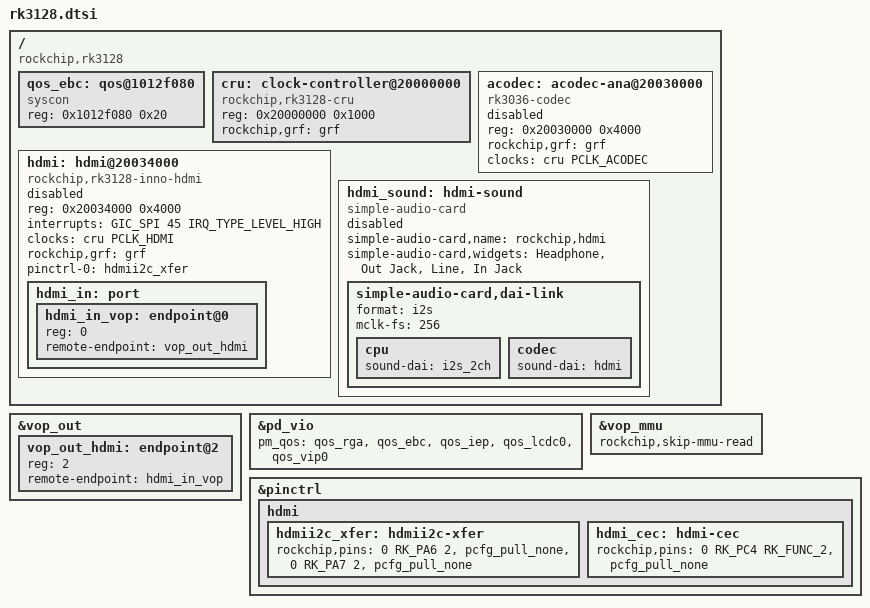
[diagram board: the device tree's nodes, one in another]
/*
 * This file is dual-licensed: you can use it either under the terms
 * of the GPL or the X11 license, at your option. Note that this dual
 * licensing only applies to this file, and not this project as a
 * whole.
 *
 *  a) This file is free software; you can redistribute it and/or
 *     modify it under the terms of the GNU General Public License as
 *     published by the Free Software Foundation; either version 2 of the
 *     License, or (at your option) any later version.
 *
 *     This file is distributed in the hope that it will be useful,
 *     but WITHOUT ANY WARRANTY; without even the implied warranty of
 *     MERCHANTABILITY or FITNESS FOR A PARTICULAR PURPOSE.  See the
 *     GNU General Public License for more details.
 *
 * Or, alternatively,
 *
 *  b) Permission is hereby granted, free of charge, to any person
 *     obtaining a copy of this software and associated documentation
 *     files (the "Software"), to deal in the Software without
 *     restriction, including without limitation the rights to use,
 *     copy, modify, merge, publish, distribute, sublicense, and/or
 *     sell copies of the Software, and to permit persons to whom the
 *     Software is furnished to do so, subject to the following
 *     conditions:
 *
 *     The above copyright notice and this permission notice shall be
 *     included in all copies or substantial portions of the Software.
 *
 *     THE SOFTWARE IS PROVIDED "AS IS", WITHOUT WARRANTY OF ANY KIND,
 *     EXPRESS OR IMPLIED, INCLUDING BUT NOT LIMITED TO THE WARRANTIES
 *     OF MERCHANTABILITY, FITNESS FOR A PARTICULAR PURPOSE AND
 *     NONINFRINGEMENT. IN NO EVENT SHALL THE AUTHORS OR COPYRIGHT
 *     HOLDERS BE LIABLE FOR ANY CLAIM, DAMAGES OR OTHER LIABILITY,
 *     WHETHER IN AN ACTION OF CONTRACT, TORT OR OTHERWISE, ARISING
 *     FROM, OUT OF OR IN CONNECTION WITH THE SOFTWARE OR THE USE OR
 *     OTHER DEALINGS IN THE SOFTWARE.
 */

#include "rk312x.dtsi"

/ {
	compatible = "rockchip,rk3128";

	qos_ebc: qos@1012f080 {
		compatible = "syscon";
		reg = <0x1012f080 0x20>;
	};

	cru: clock-controller@20000000 {
		compatible = "rockchip,rk3128-cru";
		reg = <0x20000000 0x1000>;
		rockchip,grf = <&grf>;
		#clock-cells = <1>;
		#reset-cells = <1>;
	};

	acodec: acodec-ana@20030000 {
		compatible = "rk3036-codec";
		reg = <0x20030000 0x4000>;
		rockchip,grf = <&grf>;
		clock-names = "acodec_pclk";
		clocks = <&cru PCLK_ACODEC>;
		status = "disabled";
	};

	hdmi: hdmi@20034000 {
		compatible = "rockchip,rk3128-inno-hdmi";
		reg = <0x20034000 0x4000>;
		interrupts = <GIC_SPI 45 IRQ_TYPE_LEVEL_HIGH>;
		/*
		clocks =  <&cru ACLK_VIO>, <&cru PCLK_HDMI>;
		clock-names = "aclk", "pclk";
		*/
		clocks = <&cru PCLK_HDMI>;
		clock-names = "pclk";
		rockchip,grf = <&grf>;
		pinctrl-names = "default";
		pinctrl-0 = <&hdmii2c_xfer>;
		#address-cells = <1>;
		#size-cells = <0>;
		#sound-dai-cells = <0>;
		status = "disabled";

		hdmi_in: port {
			#address-cells = <1>;
			#size-cells = <0>;
			hdmi_in_vop: endpoint@0 {
				reg = <0>;
				remote-endpoint = <&vop_out_hdmi>;
			};
		};
	};

	hdmi_sound: hdmi-sound {
		compatible = "simple-audio-card";
		simple-audio-card,name = "rockchip,hdmi";
		simple-audio-card,widgets = "Headphone", "Out Jack",
					    "Line", "In Jack";
		status = "disabled";

		simple-audio-card,dai-link {
			format = "i2s";
			mclk-fs = <256>;
			cpu {
				sound-dai = <&i2s_2ch>;
			};
			codec {
				sound-dai = <&hdmi>;
			};
		};
	};




};

&vop_out {
	vop_out_hdmi: endpoint@2 {
		reg = <2>;
		remote-endpoint = <&hdmi_in_vop>;
	};
};

&pd_vio {
	pm_qos = <&qos_rga>,
		 <&qos_ebc>,
		 <&qos_iep>,
		 <&qos_lcdc0>,
		 <&qos_vip0>;
};

&vop_mmu {
	rockchip,skip-mmu-read;
};


&pinctrl {
	hdmi {
		hdmii2c_xfer: hdmii2c-xfer {
			rockchip,pins = <0 RK_PA6 2 &pcfg_pull_none>,
					<0 RK_PA7 2 &pcfg_pull_none>;
		};

		hdmi_cec: hdmi-cec {
			rockchip,pins =
				<0 RK_PC4 RK_FUNC_2 &pcfg_pull_none>;
		};
	};
};
